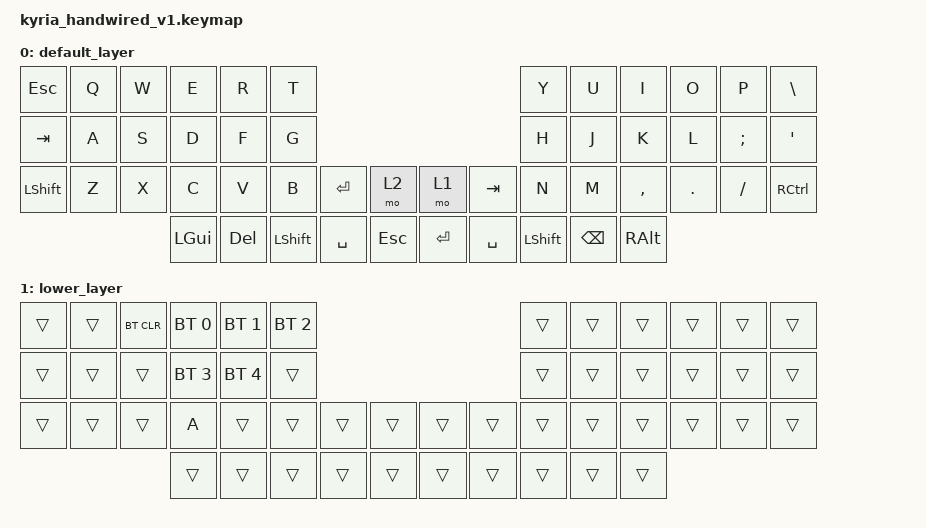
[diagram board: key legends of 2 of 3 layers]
#include <behaviors.dtsi>
#include <dt-bindings/zmk/bt.h>
#include <dt-bindings/zmk/keys.h>

/ {
    keymap {
        compatible = "zmk,keymap";

        default_layer {
            bindings = <
    &kp ESC   &kp Q &kp W &kp E    &kp R   &kp T                                                &kp Y     &kp U    &kp I     &kp O   &kp P    &kp BSLH
    &kp TAB   &kp A &kp S &kp D    &kp F   &kp G                                                &kp H     &kp J    &kp K     &kp L   &kp SEMI &kp SQT
    &kp LSHFT &kp Z &kp X &kp C    &kp V   &kp B     &kp RET   &mo 2          &mo 1   &kp TAB   &kp N     &kp M    &kp COMMA &kp DOT &kp FSLH &kp RCTRL
                          &kp LGUI &kp DEL &kp LSHFT &kp SPACE &kp ESC        &kp RET &kp SPACE &kp LSHFT &kp BSPC &kp RALT
            >;
        };
        lower_layer {
            bindings = <
    &trans &trans &bt BT_CLR &bt BT_SEL 0 &bt BT_SEL 1 &bt BT_SEL 2                                      &trans &trans &trans &trans &trans &trans
    &trans &trans &trans     &bt BT_SEL 3 &bt BT_SEL 4 &trans                                            &trans &trans &trans &trans &trans &trans
    &trans &trans &trans     &kp A        &trans       &trans       &trans &trans        &trans &trans &trans &trans &trans &trans &trans &trans
                             &trans       &trans       &trans       &trans &trans        &trans &trans &trans &trans &trans
            >;
        };
        raise_layer {
          bindings = <
    &trans &kp N1 &kp N2 &kp N3    &kp N4    &kp N5                                         &kp N6   &kp N7   &kp N8 &kp N9    &kp N0 &trans
    &trans &trans &trans &kp MINUS &kp EQUAL &trans                                         &kp LEFT &kp DOWN &kp UP &kp RIGHT &trans &trans
    &trans &trans &trans &trans    &trans    &trans &trans &trans        &trans     &trans  &trans   &trans   &trans &trans    &trans &trans
                         &trans    &trans    &trans &trans &trans        &kp LPAR &kp RPAR  &trans   &trans   &trans &trans
          >;
        };
    };
};
